# BE-U1000 register map
Vendor: BAIKAL ELECTRONICS, JSC; File version: 1.0
CPU: RISC-V r0p0, little endian, no MPU, no FPU, 3 interrupt priority bits
Registers are 32-bit, read-write, reset 0x0 unless marked. A register's access mark holds for its fields unless they carry their own. Offsets are from the block's base; [hi:lo] are bit positions; {n}, {i} and the like mark numbered series; 'fields as' and 'values as' point back to an identical list.

## I2S0 — Inter Integrated Circuit Sound Interface
Base 0x11006000
Same registers: I2S1 0x13006000
0x00 IER — Enable Register
  [0] IEN — I2S enable
    0=DISABLE; 1=ENABLE
0x04 IRER — Receiver Block Enable Register
  [0] RXEN — Receiver enable
    0=DISABLE; 1=ENABLE
0x08 ITER — Transmitter Block Enable Register
  [0] TXEN — Transmitter enable
    0=DISABLE; 1=ENABLE
0x14 RXFFR — Receiver Block FIFO Reset Register
  [0] RXFFR — Receiver FIFO reset
    0=DISABLE; 1=ENABLE
0x18 TXFFR — Transmitter Block FIFO Reset Register
  [0] TXFFR — Transmitter FIFO reset
    0=DISABLE; 1=ENABLE
0x20 LRBR0 — Left Receive Buffer Register 0
  [31:0] LRBR0 — The left stereo data received
0x20 LTHR0 — Left Transmit Holding Register 0
  [31:0] LTHR0 — The left stereo data to be transmitted
0x24 RRBR0 — Right Receive Buffer Register 0
  [31:0] RRBR0 — The right stereo data received
0x24 RTHR0 — Right Transmit Holding Register 0
  [31:0] RTHR0 — The right stereo data to be transmitted
0x28 RER0 — Receive Enable Register 0
  [0] RXCHEN0 — Receive channel 0 enable
    0=DISABLE; 1=ENABLE
0x2C TER0 — Transmit Enable Register 0
  [0] TXCHEN0 — Transmit channel 0 enable
    0=DISABLE; 1=ENABLE
0x30 RCR0 — Receive Configuration Register 0
  [2:0] WLEN — Receiver data resolution
    0=IGNORE (Ignore the word length); 1=12BIT (12-bit data resolution); 2=16BIT (16-bit data resolution); 3=20BIT (20-bit data resolution); 4=24BIT (24-bit data resolution); 5=32BIT (32-bit data resolution)
0x34 TCR0 — Transmit Configuration Register 0
  [2:0] WLEN — Transmitter data resolution
    values as RCR0.WLEN
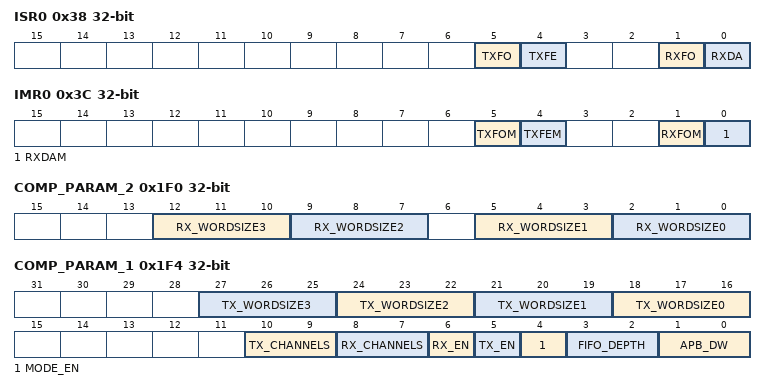
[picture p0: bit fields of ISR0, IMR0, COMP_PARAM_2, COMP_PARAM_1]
0x38 ISR0 — Interrupt Status Register 0
  [all] fields
    0=DISABLE; 1=ENABLE
  [5] TXFO — Status of Transmit Data Overrun interrupt
  [4] TXFE — Status of Transmit Empty Trigger interrupt
  [1] RXFO — Status of Receive Data Overrun interrupt
  [0] RXDA — Status of Receive Data Available interrupt
0x3C IMR0 — Interrupt Mask Register 0
  [all] fields
    0=DISABLE; 1=ENABLE
  [5] TXFOM — Mask Transmit Data Overrun interrupt
  [4] TXFEM — Mask Transmit Empty Trigger interrupt
  [1] RXFOM — Mask Receive Data Overrun interrupt
  [0] RXDAM — Mask Receive Data Available interrupt
0x40 ROR0 — Receive Overrun Register 0
  [0] RXCHO — Clear Rx FIFO Data Overrun interrupt
    0=DISABLE; 1=ENABLE
0x44 TOR0 — Transmit Overrun Register 0
  [0] TXCHO — Clear Tx FIFO Data Overrun interrupt
    0=DISABLE; 1=ENABLE
0x48 RFCR0 — Receive FIFO Configuration Register 0
  [3:0] RXCHDT — Rx FIFO trigger level
    {v}=LVL{v+1} (Rx FIFO trigger level {v+1}) (v=0..15)
0x4C TFCR0 — Transmit FIFO Configuration Register 0
  [3:0] TXCHET — Tx FIFO trigger level
    {v}=LVL{v+1} (Tx FIFO trigger level {v+1}) (v=0..15)
0x50 RFF0 — Receive FIFO Flush Register 0
  [0] RXCHFR — Receive Channel 0 FIFO reset
    0=DISABLE; 1=ENABLE
0x54 TFF0 — Transmit FIFO Flush Register 0
  [0] TXCHFR — Transmit Channel 0 FIFO reset
    0=DISABLE; 1=ENABLE
0x1C0 RXDMA — Receiver Block DMA Register
  [31:0] RXDMA — Receiver DMA register
0x1C8 TXDMA — Transmitter Block DMA Register
  [31:0] TXDMA — Transmitter DMA register
0x1F0 COMP_PARAM_2 — Component Parameter Register 2
  [all] fields
    0=12BIT (12-bit resolution); 1=16BIT (16-bit resolution); 2=20BIT (20-bit resolution); 3=24BIT (24-bit resolution); 4=32BIT (32-bit resolution)
  [12:10] RX_WORDSIZE3 — Rx resolution for WORDSIZE_3
  [9:7] RX_WORDSIZE2 — Rx resolution for WORDSIZE_2
  [5:3] RX_WORDSIZE1 — Rx resolution for WORDSIZE_1
  [2:0] RX_WORDSIZE0 — Rx resolution for WORDSIZE_0
0x1F4 COMP_PARAM_1 — Component Parameter Register 1
  [3n+18:3n+16] TX_WORDSIZE{n} (n=0..3) — Tx resolution for WORDSIZE_{n}
    values as the fields of COMP_PARAM_2
  [10:9] TX_CHANNELS — The number of Tx channels
    0=1 transmit channel; 1=2 transmit channels; 2=3 transmit channels; 3=4 transmit channels
  [8:7] RX_CHANNELS — The number of Rx channels
    0=1 receive channel; 1=2 receive channels; 2=3 receive channels; 3=4 receive channels
  [6] RX_EN — Receiver enable
    0=DISABLE; 1=ENABLE
  [5] TX_EN — Transmitter enable
    0=DISABLE; 1=ENABLE
  [4] MODE_EN — Master mode enable
    0=DISABLE; 1=ENABLE
  [3:2] FIFO_DEPTH — FIFO depth for Tx and Rx channels
    0=FIFO depth is 2; 1=FIFO depth is 4; 2=FIFO depth is 8; 3=FIFO depth is 16
  [1:0] APB_DW — APB data width
    0=8BIT (8-bit APB data width); 1=16BIT (16-bit APB data width); 2=32BIT (32-bit APB data width)
0x1F8 COMP_VERSION — Component Version Register
  [31:0] COMP_VERSION — I2S component version
0x1FC COMP_TYPE — Component Type Register
  [31:0] COMP_TYPE — I2S component type
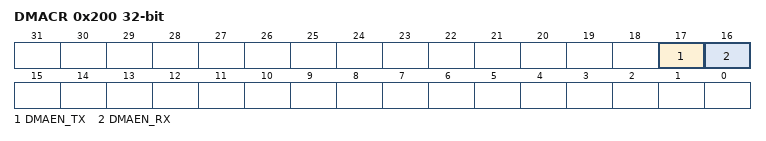
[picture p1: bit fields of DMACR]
0x200 DMACR — DMA Control Register
  [17] DMAEN_TX — Transmitter DMA enable
    0=DISABLE; 1=ENABLE
  [16] DMAEN_RX — Receiver DMA enable
    0=DISABLE; 1=ENABLE
